# STM32N647 register map
File version: 1.0
CPU: CM55 r0p1, little endian, no MPU, FPU, vendor SysTick, 8 interrupt priority bits
Registers are 32-bit, read-write, reset 0x0 unless marked. A register's access mark holds for its fields unless they carry their own. Offsets are from the block's base; [hi:lo] are bit positions; {n}, {i} and the like mark numbered series; 'fields as' and 'values as' point back to an identical list.

## EXTI — Extended interrupts and event controller
Base 0x46025000
Same registers: EXTI_S 0x56025000
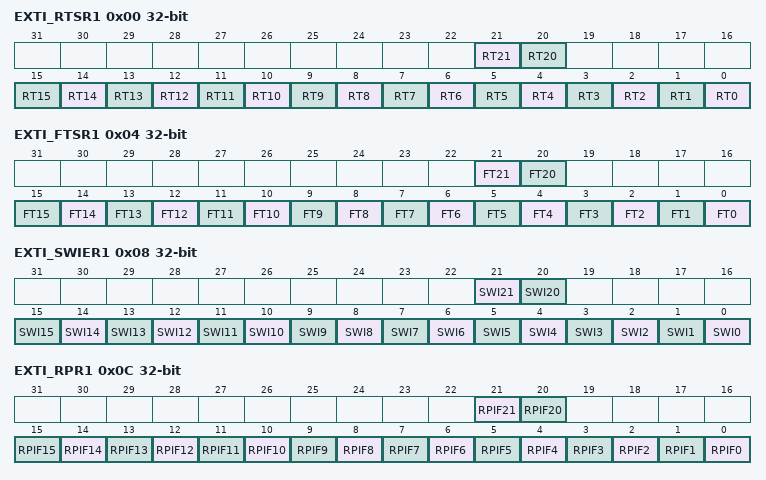
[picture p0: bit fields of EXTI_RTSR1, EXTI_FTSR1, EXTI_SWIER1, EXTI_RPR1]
0x00 EXTI_RTSR1 — EXTI rising trigger selection register
  [21] RT21 — Rising trigger event configuration bit of configurable event input x
    0=Rising trigger disabled (for event and interrupt) for input line; 1=Rising trigger enabled (for event and interrupt) for input line
  [20] RT20 — Rising trigger event configuration bit of configurable event input x
    values as RT21
  [n] RT{n} (n=0..15) — Rising trigger event configuration bit of configurable event input x
0x04 EXTI_FTSR1 — EXTI falling trigger selection register
  [21] FT21 — Falling trigger event configuration bit of configurable event input x
    0=Falling trigger disabled (for event and interrupt) for input line; 1=Falling trigger enabled (for event and interrupt) for input line
  [20] FT20 — Falling trigger event configuration bit of configurable event input x
    values as FT21
  [n] FT{n} (n=0..15) — Falling trigger event configuration bit of configurable event input x
0x08 EXTI_SWIER1 — EXTI software interrupt event register
  [21] SWI21 — Software interrupt on event x
    0=Writing 0 has no effect; 1=Writing 1 to this bit triggers a rising edge event on event x (bit auto cleared by hardware)
  [20] SWI20 — Software interrupt on event x
    values as SWI21
  [n] SWI{n} (n=0..15) — Software interrupt on event x
0x0C EXTI_RPR1 — EXTI rising edge pending register
  [21] RPIF21 — Configurable event input x rising edge pending bit
    0=No rising edge trigger request occurred; 1=Rising edge trigger request occurred
  [20] RPIF20 — Configurable event input x rising edge pending bit
    values as RPIF21
  [n] RPIF{n} (n=0..15) — Configurable event input x rising edge pending bit
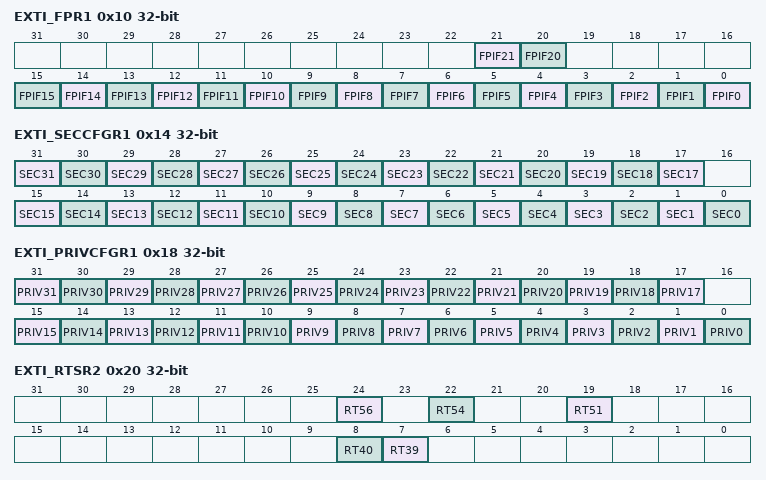
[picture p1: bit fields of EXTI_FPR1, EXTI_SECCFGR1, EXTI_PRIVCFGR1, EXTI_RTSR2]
0x10 EXTI_FPR1 — EXTI falling edge pending register
  [21] FPIF21 — configurable event input x falling edge pending bit
    0=No falling edge trigger request occurred; 1=Falling edge trigger request occurred
  [20] FPIF20 — configurable event input x falling edge pending bit
    values as FPIF21
  [n] FPIF{n} (n=0..15) — Configurable event input x rising edge pending bit
0x14 EXTI_SECCFGR1 — EXTI security configuration register
  [n] SEC{n} (n=17..31) — Security enable on event input x
    0=Event security disabled (non-secure); 1=Event security enabled (secure)
  [n] SEC{n} (n=0..15) — Security enable on event input x
0x18 EXTI_PRIVCFGR1 — EXTI privilege configuration register
  [n] PRIV{n} (n=17..31) — Privilege enable on event input x
    0=Event privilege disabled (unprivileged); 1=Event privilege enabled (privileged)
  [n] PRIV{n} (n=0..15) — Privilege enable on event input x
0x20 EXTI_RTSR2 — EXTI rising trigger selection register
  [24] RT56 — Rising trigger event configuration bit of configurable event input 56
    0=Rising trigger disabled (for event and Interrupt) for input line x; 1=Rising trigger enabled (for event and Interrupt) for input line x
  [22] RT54 — Rising trigger event configuration bit of configurable event input 54
  [19] RT51 — Rising trigger event configuration bit of configurable event input 51
  [8] RT40 — Rising trigger event configuration bit of configurable event input x
  [7] RT39 — Rising trigger event configuration bit of configurable event input x
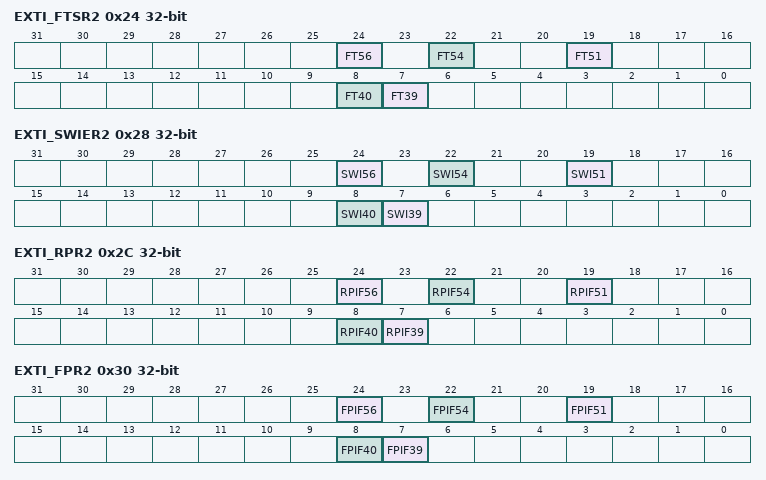
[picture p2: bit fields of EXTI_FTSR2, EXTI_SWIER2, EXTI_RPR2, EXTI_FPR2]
0x24 EXTI_FTSR2 — EXTI falling trigger selection register
  [24] FT56 — Falling trigger event configuration bit of configurable event input 56
    0=Falling trigger disabled (for event and Interrupt) for input line; 1=Falling trigger enabled (for event and Interrupt) for input line
  [22] FT54 — Falling trigger event configuration bit of configurable event input 54
  [19] FT51 — Falling trigger event configuration bit of configurable event input 51
  [8] FT40 — Falling trigger event configuration bit of configurable event input x
  [7] FT39 — Falling trigger event configuration bit of configurable event input x
0x28 EXTI_SWIER2 — EXTI software interrupt event register
  [24] SWI56 — Software interrupt on event 56
    values as EXTI_SWIER1.SWI21
  [22] SWI54 — Software interrupt on event 54
  [19] SWI51 — Software interrupt on event 51
  [8] SWI40 — Software interrupt on event x
  [7] SWI39 — Software interrupt on event x
0x2C EXTI_RPR2 — EXTI rising edge pending register
  [24] RPIF56 — Configurable event input 56 rising edge pending bit
    values as EXTI_RPR1.RPIF21
  [22] RPIF54 — Configurable event input 54 rising edge pending bit
  [19] RPIF51 — Configurable event input 51 rising edge pending bit
  [8] RPIF40 — Configurable event input x rising edge pending bit
  [7] RPIF39 — Configurable event input x rising edge pending bit
0x30 EXTI_FPR2 — EXTI falling edge pending register
  [24] FPIF56 — Configurable event input 56 falling edge pending bit
    values as EXTI_FPR1.FPIF21
  [22] FPIF54 — Configurable event input 54 falling edge pending bit
  [19] FPIF51 — Configurable event input 51 falling edge pending bit
  [8] FPIF40 — Configurable event input x falling edge pending bit
  [7] FPIF39 — Configurable event input x falling edge pending bit
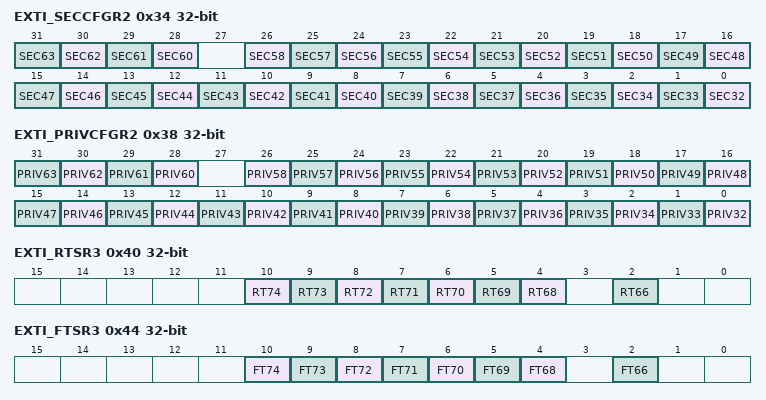
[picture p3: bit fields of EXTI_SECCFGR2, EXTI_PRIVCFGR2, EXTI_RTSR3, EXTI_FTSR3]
0x34 EXTI_SECCFGR2 — EXTI security enable register
  [n-32] SEC{n} (n=60..63) — Security enable on event input x
    values as EXTI_SECCFGR1.SEC17
  [n-32] SEC{n} (n=32..58) — Security enable on event input x
0x38 EXTI_PRIVCFGR2 — EXTI privilege enable register
  [n-32] PRIV{n} (n=60..63) — Privilege enable on event input x
    values as EXTI_PRIVCFGR1.PRIV17
  [n-32] PRIV{n} (n=32..58) — Privilege enable on event input x
0x40 EXTI_RTSR3 — EXTI rising trigger selection register
  [n-64] RT{n} (n=68..74) — Rising trigger event configuration bit of configurable event input x
    values as EXTI_RTSR1.RT21
  [2] RT66 — Rising trigger event configuration bit of configurable event input 66
0x44 EXTI_FTSR3 — EXTI falling trigger selection register
  [n-64] FT{n} (n=68..74) — Falling trigger event configuration bit of configurable event input x
    values as EXTI_FTSR1.FT21
  [2] FT66 — Falling trigger event configuration bit of configurable event input 66
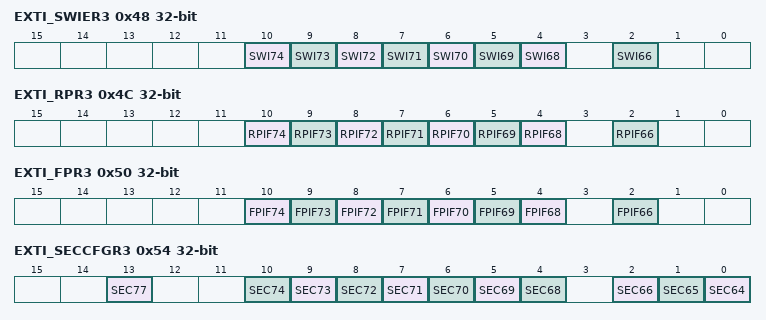
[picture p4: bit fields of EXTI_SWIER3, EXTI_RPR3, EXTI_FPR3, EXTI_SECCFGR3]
0x48 EXTI_SWIER3 — EXTI software interrupt event register
  [n-64] SWI{n} (n=68..74) — Software interrupt on event x
    values as EXTI_SWIER1.SWI21
  [2] SWI66 — Software interrupt on event 66
0x4C EXTI_RPR3 — EXTI rising edge pending register
  [n-64] RPIF{n} (n=68..74) — configurable event input x rising edge pending bit
    values as EXTI_RPR1.RPIF21
  [2] RPIF66 — configurable event input 66rising edge pending bit
0x50 EXTI_FPR3 — EXTI falling edge pending register
  [n-64] FPIF{n} (n=68..74) — configurable event input x falling edge pending bit
    values as EXTI_FPR1.FPIF21
  [2] FPIF66 — configurable event input 66 falling edge pending bit
0x54 EXTI_SECCFGR3 — EXTI security enable register
  [13] SEC77 — Security enable on event input 77
    values as EXTI_SECCFGR1.SEC17
  [n-64] SEC{n} (n=68..74) — Security enable on event input x
  [2] SEC66 — Security enable on event input x
  [1] SEC65 — Security enable on event input x
  [0] SEC64 — Security enable on event input x
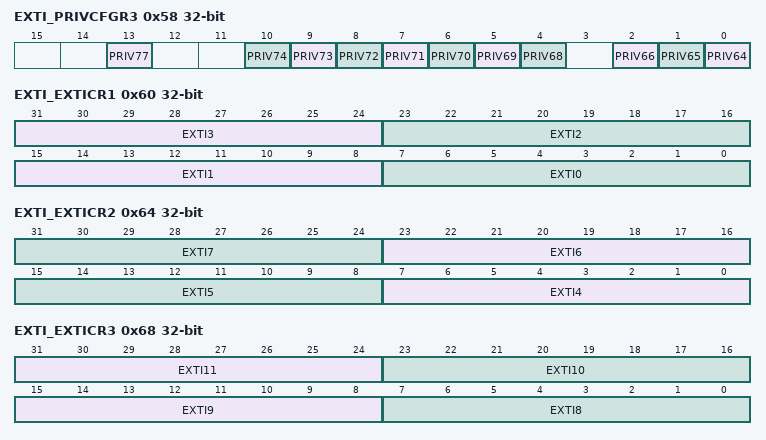
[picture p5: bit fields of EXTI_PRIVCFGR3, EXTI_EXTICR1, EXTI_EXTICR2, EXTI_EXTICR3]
0x58 EXTI_PRIVCFGR3 — EXTI privilege enable register
  [13] PRIV77 — Privilege enable on event input 77
    0=Event privilege disabled (unprivileged; 1=Event privilege enabled (privileged)
  [n-64] PRIV{n} (n=68..74) — Privilege enable on event input x
  [2] PRIV66 — Privilege enable on event input x
  [1] PRIV65 — Privilege enable on event input x
  [0] PRIV64 — Privilege enable on event input x
0x60 EXTI_EXTICR1 — EXTI external interrupt selection register 1
  [31:24] EXTI3 — EXTI3 GPIO port selection
    0=PA3 pin; 1=PB3 pin; 2=PC3 pin; 3=PD3 pin; 4=PE3 pin; 5=PF3 pin; 6=PG3 pin; 7=PH3 pin; 8=PN3 pin; 9=PO3 pin; 10=PP3 pin; 11=PQ3 pin
  [23:16] EXTI2 — EXTI2 GPIO port selection
    0=PA2 pin; 1=PB2 pin; 2=PC2 pin; 3=PD2 pin; 4=PE2 pin; 5=PF2 pin; 6=PG2 pin; 7=PH2 pin; 8=PN2 pin; 9=PO2 pin; 10=PP2 pin; 11=PQ2 pin
  [15:8] EXTI1 — EXTI1 GPIO port selection
    0=PA1 pin; 1=PB1 pin; 2=PC1 pin; 3=PD1 pin; 4=PE1 pin; 5=PF1 pin; 6=PG1 pin; 7=PH1 pin; 8=PN1 pin; 9=PO1 pin; 10=PP1 pin; 11=PQ1 pin
  [7:0] EXTI0 — EXTI0 GPIO port selection.
    0=PA0 pin; 1=PB0 pin; 2=PC0 pin; 3=PD0 pin; 4=PE0 pin; 5=PF0 pin; 6=PG0 pin; 7=PH0 pin; 8=PN0 pin; 9=PO0 pin; 10=PP0 pin; 11=PQ0 pin
0x64 EXTI_EXTICR2 — EXTI external interrupt selection register 2
  [8n-25:8n-32] EXTI{n} (n=4..7) — EXTI{n} GPIO port selection.
    0=PA{n} pin; 1=PB{n} pin; 2=PC{n} pin; 3=PD{n} pin; 4=PE{n} pin; 5=PF{n} pin; 6=PG{n} pin; 7=PH{n} pin; 8=PN{n} pin; 9=PO{n} pin; 10=PP{n} pin; 11=PQ{n} pin
0x68 EXTI_EXTICR3 — EXTI external interrupt selection register 3
  [31:24] EXTI11 — EXTI11 GPIO port selection.
    0=PA11 pin; 1=PB11 pin; 2=PC11 pin; 3=PD11 pin; 4=PE11 pin; 5=PF11 pin; 6=PG11 pin; 7=PH11 pin; 8=PN11 pin; 9=PO11 pin; 10=PO11 pin; 11=PQ11 pin
  [23:16] EXTI10 — EXTI10 GPIO port selection.
    0=PA10 pin; 1=PB10 pin; 2=PC10 pin; 3=PD10 pin; 4=PE10 pin; 5=PF10 pin; 6=PG10 pin; 7=PH10 pin; 8=PN10 pin; 9=PO10 pin; 10=PP10 pin; 11=PQ10 pin
  [15:8] EXTI9 — EXTI9 GPIO port selection.
    0=PA9 pin; 1=PB9 pin; 2=PC9 pin; 3=PD9 pin; 4=PE9 pin; 5=PF9 pin; 6=PG9 pin; 7=PH9 pin; 8=PN9 pin; 9=PO9 pin; 10=PP9 pin; 11=PQ9 pin
  [7:0] EXTI8 — EXTI8 GPIO port selection.
    0=PA8 pin; 1=PB8 pin; 2=PC8 pin; 3=PD8 pin; 4=PE8 pin; 5=PF8 pin; 6=PG8 pin; 7=PH8 pin; 8=PN8 pin; 9=PO8 pin; 10=PP8 pin; 11=PQ8 pin
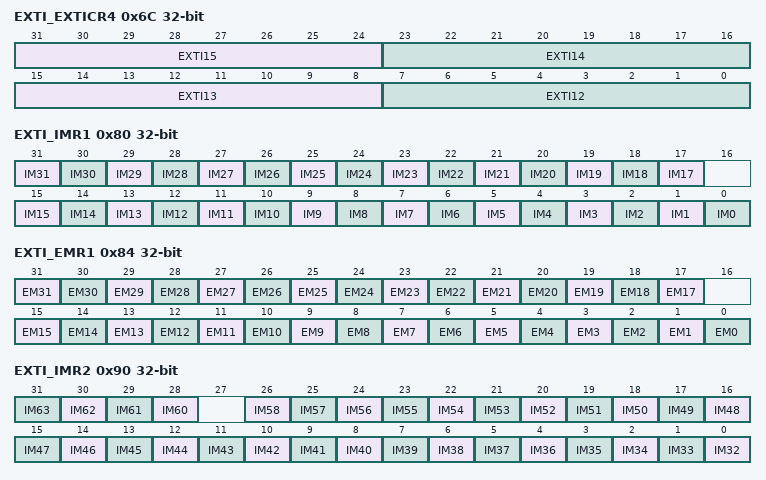
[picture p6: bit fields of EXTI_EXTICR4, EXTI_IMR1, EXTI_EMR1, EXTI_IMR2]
0x6C EXTI_EXTICR4 — EXTI external interrupt selection register 4
  [31:24] EXTI15 — EXTI15 GPIO port selection.
    0=PA15 pin; 1=PB15 pin; 2=PC15 pin; 3=PD15 pin; 4=PE15 pin; 5=PF15 pin; 6=PG15 pin; 7=PH15 pin; 8=PN15 pin; 9=PO15 pin; 10=PP15 pin; 11=PQ15 pin
  [23:16] EXTI14 — EXTI14 GPIO port selection.
    0=PA14 pin; 1=PB14 pin; 2=PC14 pin; 3=PD14 pin; 4=PE14 pin; 5=PF14 pin; 6=PG14 pin; 7=PH14 pin; 8=PN14 pin; 9=PO14 pin; 10=PP14 pin; 11=PQ14 pin
  [15:8] EXTI13 — EXTI13 GPIO port selection.
    0=PA13 pin; 1=PB13 pin; 2=PC13 pin; 3=PD13 pin; 4=PE13 pin; 5=PF13 pin; 6=PG13 pin; 7=PH13 pin; 8=PO13 pin; 9=PP13 pin; 10=PQ13 pin; 11=PN13 pin
  [7:0] EXTI12 — EXTI12 GPIO port selection.
    0=PA12 pin; 1=PB12 pin; 2=PC12 pin; 3=PD12 pin; 4=PE12 pin; 5=PF12 pin; 6=PG12 pin; 7=PH12 pin; 8=PO12 pin; 9=PP12 pin; 10=PQ12 pin; 11=PN12 pin
0x70 EXTI_LOCKR — EXTI lock register
  [0] GLOCK — Global security privilege EXTI_SECCFGRx/PRIVCFGRx
    0=Security, privilege open can be modified; 1=Security, privilege locked can no longer be modified
0x80 EXTI_IMR1 — EXTI CPU wake-up with interrupt mask register 1
  [n] IM{n} (n=17..31) — CPU wake-up with interrupt mask on event input x
    0=Wake-up and interrupt from input event x is masked; 1=Wake-up and interrupt from input event x is unmasked. CPU wake-up event and configurable event interrupt generated.
  [n] IM{n} (n=0..15) — CPU wake-up with interrupt mask on event input x
0x84 EXTI_EMR1 — EXTI CPU wake-up with event mask register 1
  [n] EM{n} (n=17..31) — CPU wake-up with event on event input x
    0=Wake-up with event request from line x is masked; 1=Wake-up with event request from line x is unmasked
  [n] EM{n} (n=0..15) — CPU wake-up with interrupt mask on event input x
0x90 EXTI_IMR2 — EXTI CPU wake-up with interrupt mask register 2
  [n-32] IM{n} (n=60..63) — CPU wake-up with interrupt mask on event input x
    values as EXTI_IMR1.IM17
  [n-32] IM{n} (n=32..58) — CPU wake-up with interrupt mask on event input x
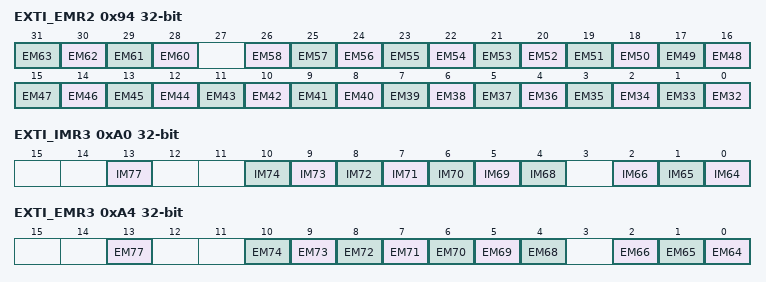
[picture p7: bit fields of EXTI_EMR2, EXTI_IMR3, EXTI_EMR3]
0x94 EXTI_EMR2 — EXTI CPU wake-up with event mask register 2
  [n-32] EM{n} (n=60..63) — CPU wake-up with event on event input x
    values as EXTI_EMR1.EM17
  [n-32] EM{n} (n=32..58) — CPU wake-up with interrupt mask on event input x
0xA0 EXTI_IMR3 — EXTI CPU wake-up with interrupt mask register 3
  [13] IM77 — CPU wake-up with interrupt mask on event input 77
    values as EXTI_IMR1.IM17
  [n-64] IM{n} (n=68..74) — CPU wake-up with interrupt mask on event input x
  [2] IM66 — CPU wake-up with interrupt mask on event input x
  [1] IM65 — CPU wake-up with interrupt mask on event input x
  [0] IM64 — CPU wake-up with interrupt mask on event input x
0xA4 EXTI_EMR3 — EXTI CPU wake-up with event mask register 3
  [13] EM77 — CPU wake-up with event on event input 77
    values as EXTI_EMR1.EM17
  [n-64] EM{n} (n=68..74) — CPU wake-up with interrupt mask on event input x
  [2] EM66 — CPU wake-up with interrupt mask on event input x
  [1] EM65 — CPU wake-up with interrupt mask on event input x
  [0] EM64 — CPU wake-up with interrupt mask on event input x
